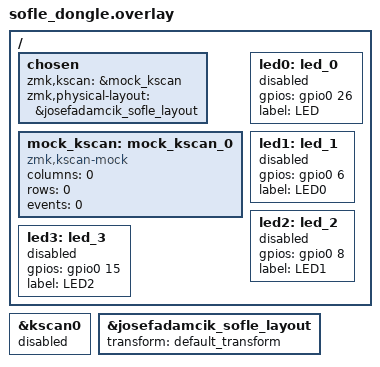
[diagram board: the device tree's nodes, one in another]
#include "sofle.dtsi"

&kscan0 {
    status = "disabled";
};

&josefadamcik_sofle_layout {
    transform = <&default_transform>;
};

/ {
    chosen {
        zmk,kscan = &mock_kscan;
        zmk,physical-layout = &josefadamcik_sofle_layout;
    };

    mock_kscan: mock_kscan_0 {
        compatible = "zmk,kscan-mock";
        columns = <0>;
        rows = <0>;
        events = <0>;
    };
};


/ {
    led0: led_0 {
        gpios = <&gpio0 26 GPIO_ACTIVE_HIGH>;
        label = "LED";
        status = "disabled";
    };
    led1: led_1 {
        gpios = <&gpio0 6 GPIO_ACTIVE_HIGH>;
        label = "LED0";
        status = "disabled";
    };
    led2: led_2 {
        gpios = <&gpio0 8 GPIO_ACTIVE_HIGH>;
        label = "LED1";
        status = "disabled";
    };
    led3: led_3 {
        gpios = <&gpio0 15 GPIO_ACTIVE_HIGH>;
        label = "LED2";
        status = "disabled";
    };
};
